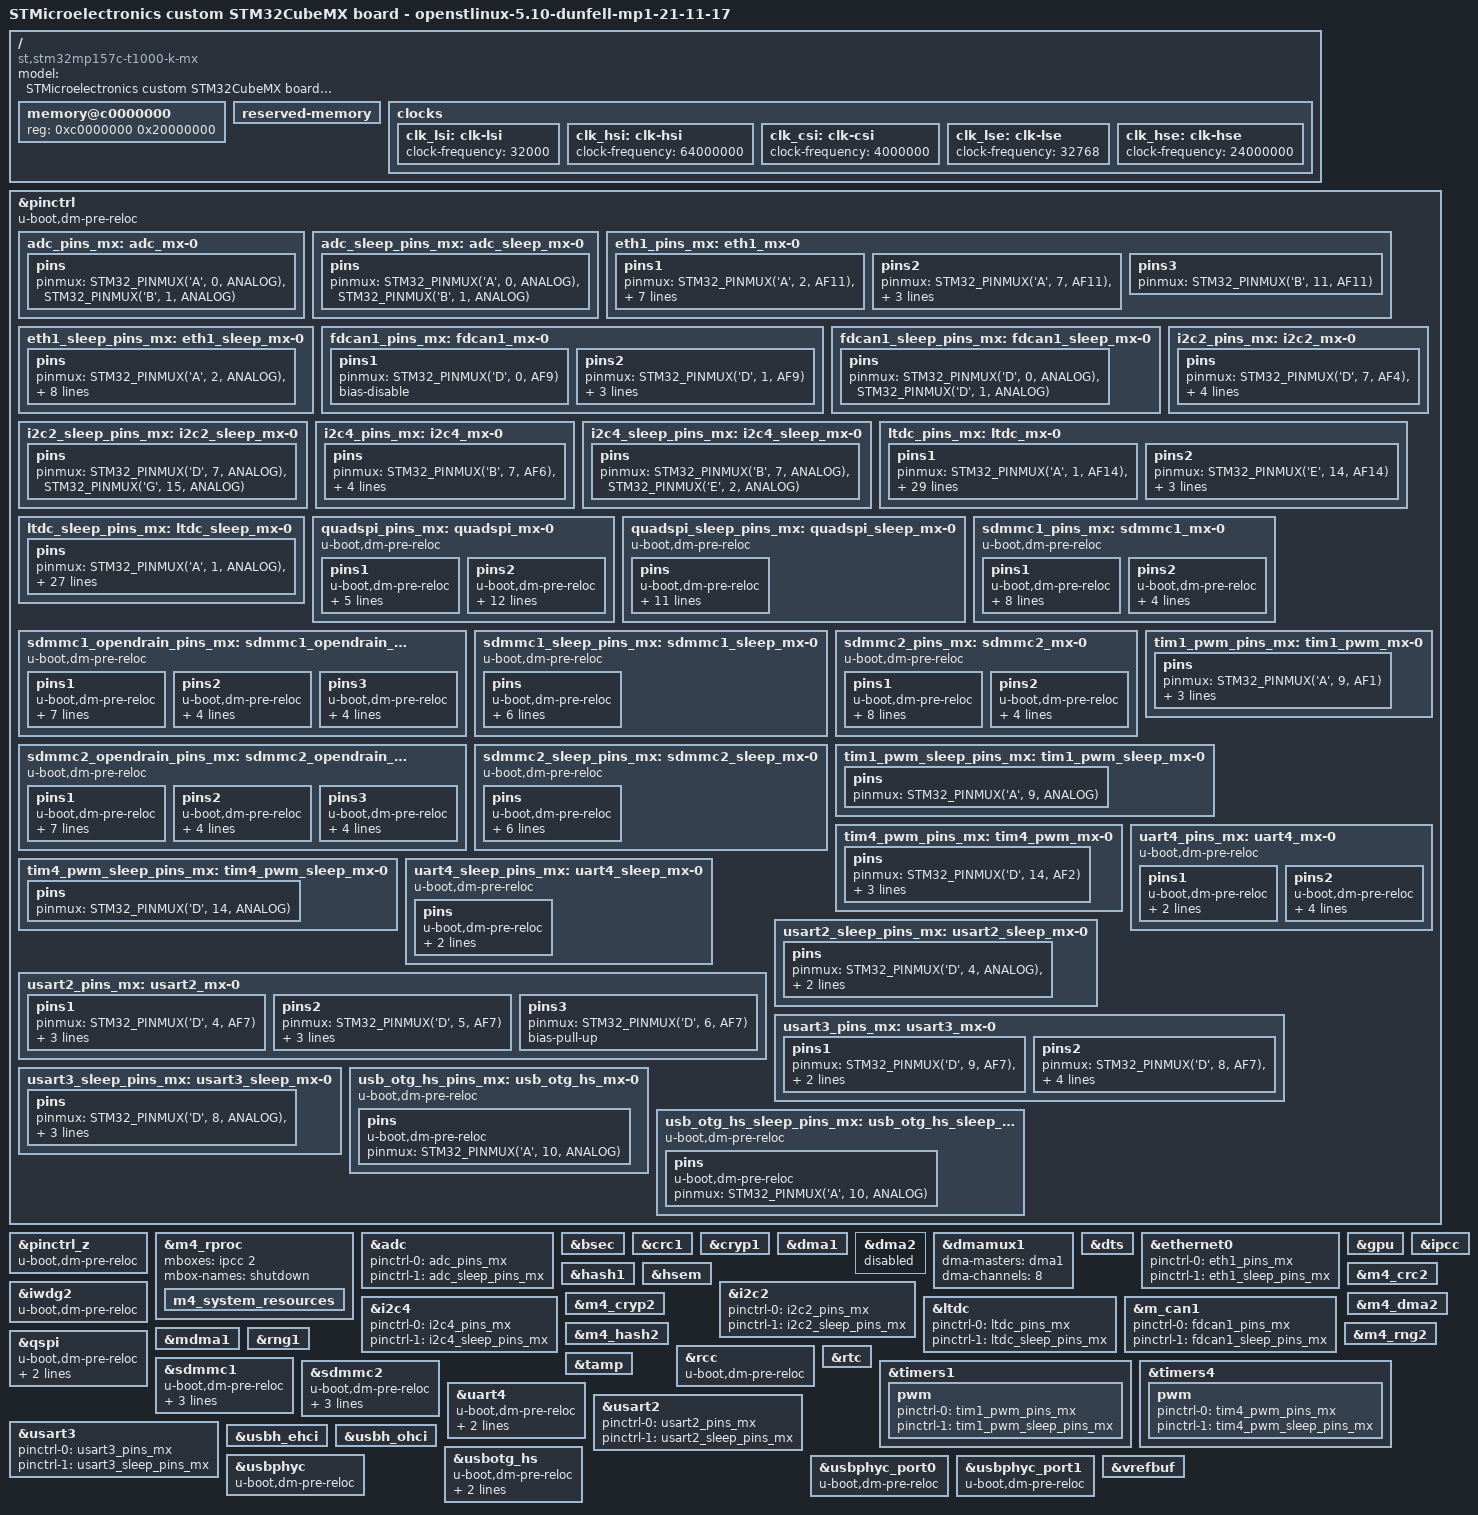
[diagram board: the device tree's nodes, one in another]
/* SPDX-License-Identifier: (GPL-2.0+ OR BSD-3-Clause) */
/*
 * Copyright (C) STMicroelectronics 2022 - All Rights Reserved
 * Author: STM32CubeMX code generation for STMicroelectronics.
 */

/* For more information on Device Tree configuration, please refer to
 * https://wiki.st.com/stm32mpu/wiki/Category:Device_tree_configuration
 */

/dts-v1/;
#include <dt-bindings/pinctrl/stm32-pinfunc.h>

#include "stm32mp157.dtsi"
#include "stm32mp15xc.dtsi"
#include "stm32mp15xxad-pinctrl.dtsi"
#include "stm32mp15-m4-srm.dtsi"

/* USER CODE BEGIN includes */
/* USER CODE END includes */

/ {
	model = "STMicroelectronics custom STM32CubeMX board - openstlinux-5.10-dunfell-mp1-21-11-17";
	compatible = "st,stm32mp157c-t1000-k-mx", "st,stm32mp157";

	memory@c0000000 {
		device_type = "memory";
		reg = <0xc0000000 0x20000000>;

		/* USER CODE BEGIN memory */
		/* USER CODE END memory */
	};

	reserved-memory {
		#address-cells = <1>;
		#size-cells = <1>;
		ranges;

		/* USER CODE BEGIN reserved-memory */
		/* USER CODE END reserved-memory */
	};

	/* USER CODE BEGIN root */
	/* USER CODE END root */

	clocks {
		/* USER CODE BEGIN clocks */
		/* USER CODE END clocks */

#ifndef CONFIG_TFABOOT
		clk_lsi: clk-lsi {
			clock-frequency = <32000>;
		};
		clk_hsi: clk-hsi {
			clock-frequency = <64000000>;
		};
		clk_csi: clk-csi {
			clock-frequency = <4000000>;
		};
		clk_lse: clk-lse {
			clock-frequency = <32768>;
		};
		clk_hse: clk-hse {
			clock-frequency = <24000000>;
		};
#endif	/*CONFIG_TFABOOT*/
	};

}; /*root*/

&pinctrl {
	u-boot,dm-pre-reloc;

	adc_pins_mx: adc_mx-0 {
		pins {
			pinmux = <STM32_PINMUX('A', 0, ANALOG)>, /* ADC1_INP16 */
					 <STM32_PINMUX('B', 1, ANALOG)>; /* ADC1_INP5 */
		};
	};

	adc_sleep_pins_mx: adc_sleep_mx-0 {
		pins {
			pinmux = <STM32_PINMUX('A', 0, ANALOG)>, /* ADC1_INP16 */
					 <STM32_PINMUX('B', 1, ANALOG)>; /* ADC1_INP5 */
		};
	};

	eth1_pins_mx: eth1_mx-0 {
		pins1 {
			pinmux = <STM32_PINMUX('A', 2, AF11)>, /* ETH1_MDIO */
					 <STM32_PINMUX('B', 12, AF11)>, /* ETH1_TXD0 */
					 <STM32_PINMUX('B', 13, AF11)>, /* ETH1_TXD1 */
					 <STM32_PINMUX('C', 1, AF11)>, /* ETH1_MDC */
					 <STM32_PINMUX('G', 8, AF2)>; /* ETH1_CLK */
			bias-disable;
			drive-push-pull;
			slew-rate = <1>;
		};
		pins2 {
			pinmux = <STM32_PINMUX('A', 7, AF11)>, /* ETH1_CRS_DV */
					 <STM32_PINMUX('C', 4, AF11)>, /* ETH1_RXD0 */
					 <STM32_PINMUX('C', 5, AF11)>; /* ETH1_RXD1 */
			bias-disable;
		};
		pins3 {
			pinmux = <STM32_PINMUX('B', 11, AF11)>; /* ETH1_TX_EN */
		};
	};

	eth1_sleep_pins_mx: eth1_sleep_mx-0 {
		pins {
			pinmux = <STM32_PINMUX('A', 2, ANALOG)>, /* ETH1_MDIO */
					 <STM32_PINMUX('A', 7, ANALOG)>, /* ETH1_CRS_DV */
					 <STM32_PINMUX('B', 11, ANALOG)>, /* ETH1_TX_EN */
					 <STM32_PINMUX('B', 12, ANALOG)>, /* ETH1_TXD0 */
					 <STM32_PINMUX('B', 13, ANALOG)>, /* ETH1_TXD1 */
					 <STM32_PINMUX('C', 1, ANALOG)>, /* ETH1_MDC */
					 <STM32_PINMUX('C', 4, ANALOG)>, /* ETH1_RXD0 */
					 <STM32_PINMUX('C', 5, ANALOG)>, /* ETH1_RXD1 */
					 <STM32_PINMUX('G', 8, ANALOG)>; /* ETH1_CLK */
		};
	};

	fdcan1_pins_mx: fdcan1_mx-0 {
		pins1 {
			pinmux = <STM32_PINMUX('D', 0, AF9)>; /* FDCAN1_RX */
			bias-disable;
		};
		pins2 {
			pinmux = <STM32_PINMUX('D', 1, AF9)>; /* FDCAN1_TX */
			bias-disable;
			drive-push-pull;
			slew-rate = <0>;
		};
	};

	fdcan1_sleep_pins_mx: fdcan1_sleep_mx-0 {
		pins {
			pinmux = <STM32_PINMUX('D', 0, ANALOG)>, /* FDCAN1_RX */
					 <STM32_PINMUX('D', 1, ANALOG)>; /* FDCAN1_TX */
		};
	};

	i2c2_pins_mx: i2c2_mx-0 {
		pins {
			pinmux = <STM32_PINMUX('D', 7, AF4)>, /* I2C2_SCL */
					 <STM32_PINMUX('G', 15, AF4)>; /* I2C2_SDA */
			bias-pull-up;
			drive-open-drain;
			slew-rate = <0>;
		};
	};

	i2c2_sleep_pins_mx: i2c2_sleep_mx-0 {
		pins {
			pinmux = <STM32_PINMUX('D', 7, ANALOG)>, /* I2C2_SCL */
					 <STM32_PINMUX('G', 15, ANALOG)>; /* I2C2_SDA */
		};
	};

	i2c4_pins_mx: i2c4_mx-0 {
		pins {
			pinmux = <STM32_PINMUX('B', 7, AF6)>, /* I2C4_SDA */
					 <STM32_PINMUX('E', 2, AF4)>; /* I2C4_SCL */
			bias-pull-up;
			drive-open-drain;
			slew-rate = <0>;
		};
	};

	i2c4_sleep_pins_mx: i2c4_sleep_mx-0 {
		pins {
			pinmux = <STM32_PINMUX('B', 7, ANALOG)>, /* I2C4_SDA */
					 <STM32_PINMUX('E', 2, ANALOG)>; /* I2C4_SCL */
		};
	};

	ltdc_pins_mx: ltdc_mx-0 {
		pins1 {
			pinmux = <STM32_PINMUX('A', 1, AF14)>, /* LTDC_R2 */
					 <STM32_PINMUX('A', 3, AF14)>, /* LTDC_B5 */
					 <STM32_PINMUX('A', 4, AF14)>, /* LTDC_VSYNC */
					 <STM32_PINMUX('A', 5, AF14)>, /* LTDC_R4 */
					 <STM32_PINMUX('A', 6, AF14)>, /* LTDC_G2 */
					 <STM32_PINMUX('A', 8, AF14)>, /* LTDC_R6 */
					 <STM32_PINMUX('A', 12, AF14)>, /* LTDC_R5 */
					 <STM32_PINMUX('A', 15, AF14)>, /* LTDC_R1 */
					 <STM32_PINMUX('B', 0, AF9)>, /* LTDC_R3 */
					 <STM32_PINMUX('B', 5, AF14)>, /* LTDC_G7 */
					 <STM32_PINMUX('B', 8, AF14)>, /* LTDC_B6 */
					 <STM32_PINMUX('B', 9, AF14)>, /* LTDC_B7 */
					 <STM32_PINMUX('B', 10, AF14)>, /* LTDC_G4 */
					 <STM32_PINMUX('C', 6, AF14)>, /* LTDC_HSYNC */
					 <STM32_PINMUX('C', 7, AF14)>, /* LTDC_G6 */
					 <STM32_PINMUX('D', 10, AF14)>, /* LTDC_B3 */
					 <STM32_PINMUX('E', 4, AF14)>, /* LTDC_B0 */
					 <STM32_PINMUX('E', 5, AF14)>, /* LTDC_G0 */
					 <STM32_PINMUX('E', 6, AF14)>, /* LTDC_G1 */
					 <STM32_PINMUX('E', 11, AF14)>, /* LTDC_G3 */
					 <STM32_PINMUX('E', 12, AF14)>, /* LTDC_B4 */
					 <STM32_PINMUX('E', 13, AF14)>, /* LTDC_DE */
					 <STM32_PINMUX('E', 15, AF14)>, /* LTDC_R7 */
					 <STM32_PINMUX('F', 11, AF14)>, /* LTDC_G5 */
					 <STM32_PINMUX('G', 10, AF14)>, /* LTDC_B2 */
					 <STM32_PINMUX('G', 12, AF14)>, /* LTDC_B1 */
					 <STM32_PINMUX('G', 13, AF14)>; /* LTDC_R0 */
			bias-disable;
			drive-push-pull;
			slew-rate = <0>;
		};
		pins2 {
			pinmux = <STM32_PINMUX('E', 14, AF14)>; /* LTDC_CLK */
			bias-disable;
			drive-push-pull;
			slew-rate = <1>;
		};
	};

	ltdc_sleep_pins_mx: ltdc_sleep_mx-0 {
		pins {
			pinmux = <STM32_PINMUX('A', 1, ANALOG)>, /* LTDC_R2 */
					 <STM32_PINMUX('A', 3, ANALOG)>, /* LTDC_B5 */
					 <STM32_PINMUX('A', 4, ANALOG)>, /* LTDC_VSYNC */
					 <STM32_PINMUX('A', 5, ANALOG)>, /* LTDC_R4 */
					 <STM32_PINMUX('A', 6, ANALOG)>, /* LTDC_G2 */
					 <STM32_PINMUX('A', 8, ANALOG)>, /* LTDC_R6 */
					 <STM32_PINMUX('A', 12, ANALOG)>, /* LTDC_R5 */
					 <STM32_PINMUX('A', 15, ANALOG)>, /* LTDC_R1 */
					 <STM32_PINMUX('B', 0, ANALOG)>, /* LTDC_R3 */
					 <STM32_PINMUX('B', 5, ANALOG)>, /* LTDC_G7 */
					 <STM32_PINMUX('B', 8, ANALOG)>, /* LTDC_B6 */
					 <STM32_PINMUX('B', 9, ANALOG)>, /* LTDC_B7 */
					 <STM32_PINMUX('B', 10, ANALOG)>, /* LTDC_G4 */
					 <STM32_PINMUX('C', 6, ANALOG)>, /* LTDC_HSYNC */
					 <STM32_PINMUX('C', 7, ANALOG)>, /* LTDC_G6 */
					 <STM32_PINMUX('D', 10, ANALOG)>, /* LTDC_B3 */
					 <STM32_PINMUX('E', 4, ANALOG)>, /* LTDC_B0 */
					 <STM32_PINMUX('E', 5, ANALOG)>, /* LTDC_G0 */
					 <STM32_PINMUX('E', 6, ANALOG)>, /* LTDC_G1 */
					 <STM32_PINMUX('E', 11, ANALOG)>, /* LTDC_G3 */
					 <STM32_PINMUX('E', 12, ANALOG)>, /* LTDC_B4 */
					 <STM32_PINMUX('E', 13, ANALOG)>, /* LTDC_DE */
					 <STM32_PINMUX('E', 14, ANALOG)>, /* LTDC_CLK */
					 <STM32_PINMUX('E', 15, ANALOG)>, /* LTDC_R7 */
					 <STM32_PINMUX('F', 11, ANALOG)>, /* LTDC_G5 */
					 <STM32_PINMUX('G', 10, ANALOG)>, /* LTDC_B2 */
					 <STM32_PINMUX('G', 12, ANALOG)>, /* LTDC_B1 */
					 <STM32_PINMUX('G', 13, ANALOG)>; /* LTDC_R0 */
		};
	};

	quadspi_pins_mx: quadspi_mx-0 {
		u-boot,dm-pre-reloc;
		pins1 {
			u-boot,dm-pre-reloc;
			pinmux = <STM32_PINMUX('B', 6, AF10)>, /* QUADSPI_BK1_NCS */
					 <STM32_PINMUX('C', 0, AF10)>; /* QUADSPI_BK2_NCS */
			bias-pull-up;
			drive-push-pull;
			slew-rate = <3>;
		};
		pins2 {
			u-boot,dm-pre-reloc;
			pinmux = <STM32_PINMUX('E', 7, AF10)>, /* QUADSPI_BK2_IO0 */
					 <STM32_PINMUX('E', 8, AF10)>, /* QUADSPI_BK2_IO1 */
					 <STM32_PINMUX('E', 9, AF10)>, /* QUADSPI_BK2_IO2 */
					 <STM32_PINMUX('E', 10, AF10)>, /* QUADSPI_BK2_IO3 */
					 <STM32_PINMUX('F', 6, AF9)>, /* QUADSPI_BK1_IO3 */
					 <STM32_PINMUX('F', 7, AF9)>, /* QUADSPI_BK1_IO2 */
					 <STM32_PINMUX('F', 8, AF10)>, /* QUADSPI_BK1_IO0 */
					 <STM32_PINMUX('F', 9, AF10)>, /* QUADSPI_BK1_IO1 */
					 <STM32_PINMUX('F', 10, AF9)>; /* QUADSPI_CLK */
			bias-disable;
			drive-push-pull;
			slew-rate = <3>;
		};
	};

	quadspi_sleep_pins_mx: quadspi_sleep_mx-0 {
		u-boot,dm-pre-reloc;
		pins {
			u-boot,dm-pre-reloc;
			pinmux = <STM32_PINMUX('B', 6, ANALOG)>, /* QUADSPI_BK1_NCS */
					 <STM32_PINMUX('C', 0, ANALOG)>, /* QUADSPI_BK2_NCS */
					 <STM32_PINMUX('E', 7, ANALOG)>, /* QUADSPI_BK2_IO0 */
					 <STM32_PINMUX('E', 8, ANALOG)>, /* QUADSPI_BK2_IO1 */
					 <STM32_PINMUX('E', 9, ANALOG)>, /* QUADSPI_BK2_IO2 */
					 <STM32_PINMUX('E', 10, ANALOG)>, /* QUADSPI_BK2_IO3 */
					 <STM32_PINMUX('F', 6, ANALOG)>, /* QUADSPI_BK1_IO3 */
					 <STM32_PINMUX('F', 7, ANALOG)>, /* QUADSPI_BK1_IO2 */
					 <STM32_PINMUX('F', 8, ANALOG)>, /* QUADSPI_BK1_IO0 */
					 <STM32_PINMUX('F', 9, ANALOG)>, /* QUADSPI_BK1_IO1 */
					 <STM32_PINMUX('F', 10, ANALOG)>; /* QUADSPI_CLK */
		};
	};

	sdmmc1_pins_mx: sdmmc1_mx-0 {
		u-boot,dm-pre-reloc;
		pins1 {
			u-boot,dm-pre-reloc;
			pinmux = <STM32_PINMUX('C', 8, AF12)>, /* SDMMC1_D0 */
					 <STM32_PINMUX('C', 9, AF12)>, /* SDMMC1_D1 */
					 <STM32_PINMUX('C', 10, AF12)>, /* SDMMC1_D2 */
					 <STM32_PINMUX('C', 11, AF12)>, /* SDMMC1_D3 */
					 <STM32_PINMUX('D', 2, AF12)>; /* SDMMC1_CMD */
			bias-pull-up;
			drive-push-pull;
			slew-rate = <1>;
		};
		pins2 {
			u-boot,dm-pre-reloc;
			pinmux = <STM32_PINMUX('C', 12, AF12)>; /* SDMMC1_CK */
			bias-pull-up;
			drive-push-pull;
			slew-rate = <3>;
		};
	};

	sdmmc1_opendrain_pins_mx: sdmmc1_opendrain_mx-0 {
		u-boot,dm-pre-reloc;
		pins1 {
			u-boot,dm-pre-reloc;
			pinmux = <STM32_PINMUX('C', 8, AF12)>, /* SDMMC1_D0 */
					 <STM32_PINMUX('C', 9, AF12)>, /* SDMMC1_D1 */
					 <STM32_PINMUX('C', 10, AF12)>, /* SDMMC1_D2 */
					 <STM32_PINMUX('C', 11, AF12)>; /* SDMMC1_D3 */
			bias-pull-up;
			drive-push-pull;
			slew-rate = <1>;
		};
		pins2 {
			u-boot,dm-pre-reloc;
			pinmux = <STM32_PINMUX('C', 12, AF12)>; /* SDMMC1_CK */
			bias-pull-up;
			drive-push-pull;
			slew-rate = <3>;
		};
		pins3 {
			u-boot,dm-pre-reloc;
			pinmux = <STM32_PINMUX('D', 2, AF12)>; /* SDMMC1_CMD */
			bias-pull-up;
			drive-open-drain;
			slew-rate = <1>;
		};
	};

	sdmmc1_sleep_pins_mx: sdmmc1_sleep_mx-0 {
		u-boot,dm-pre-reloc;
		pins {
			u-boot,dm-pre-reloc;
			pinmux = <STM32_PINMUX('C', 8, ANALOG)>, /* SDMMC1_D0 */
					 <STM32_PINMUX('C', 9, ANALOG)>, /* SDMMC1_D1 */
					 <STM32_PINMUX('C', 10, ANALOG)>, /* SDMMC1_D2 */
					 <STM32_PINMUX('C', 11, ANALOG)>, /* SDMMC1_D3 */
					 <STM32_PINMUX('C', 12, ANALOG)>, /* SDMMC1_CK */
					 <STM32_PINMUX('D', 2, ANALOG)>; /* SDMMC1_CMD */
		};
	};

	sdmmc2_pins_mx: sdmmc2_mx-0 {
		u-boot,dm-pre-reloc;
		pins1 {
			u-boot,dm-pre-reloc;
			pinmux = <STM32_PINMUX('B', 3, AF9)>, /* SDMMC2_D2 */
					 <STM32_PINMUX('B', 4, AF9)>, /* SDMMC2_D3 */
					 <STM32_PINMUX('B', 14, AF9)>, /* SDMMC2_D0 */
					 <STM32_PINMUX('B', 15, AF9)>, /* SDMMC2_D1 */
					 <STM32_PINMUX('G', 6, AF10)>; /* SDMMC2_CMD */
			bias-pull-up;
			drive-push-pull;
			slew-rate = <1>;
		};
		pins2 {
			u-boot,dm-pre-reloc;
			pinmux = <STM32_PINMUX('E', 3, AF9)>; /* SDMMC2_CK */
			bias-pull-up;
			drive-push-pull;
			slew-rate = <3>;
		};
	};

	sdmmc2_opendrain_pins_mx: sdmmc2_opendrain_mx-0 {
		u-boot,dm-pre-reloc;
		pins1 {
			u-boot,dm-pre-reloc;
			pinmux = <STM32_PINMUX('B', 3, AF9)>, /* SDMMC2_D2 */
					 <STM32_PINMUX('B', 4, AF9)>, /* SDMMC2_D3 */
					 <STM32_PINMUX('B', 14, AF9)>, /* SDMMC2_D0 */
					 <STM32_PINMUX('B', 15, AF9)>; /* SDMMC2_D1 */
			bias-pull-up;
			drive-push-pull;
			slew-rate = <1>;
		};
		pins2 {
			u-boot,dm-pre-reloc;
			pinmux = <STM32_PINMUX('E', 3, AF9)>; /* SDMMC2_CK */
			bias-pull-up;
			drive-push-pull;
			slew-rate = <3>;
		};
		pins3 {
			u-boot,dm-pre-reloc;
			pinmux = <STM32_PINMUX('G', 6, AF10)>; /* SDMMC2_CMD */
			bias-pull-up;
			drive-open-drain;
			slew-rate = <1>;
		};
	};

	sdmmc2_sleep_pins_mx: sdmmc2_sleep_mx-0 {
		u-boot,dm-pre-reloc;
		pins {
			u-boot,dm-pre-reloc;
			pinmux = <STM32_PINMUX('B', 3, ANALOG)>, /* SDMMC2_D2 */
					 <STM32_PINMUX('B', 4, ANALOG)>, /* SDMMC2_D3 */
					 <STM32_PINMUX('B', 14, ANALOG)>, /* SDMMC2_D0 */
					 <STM32_PINMUX('B', 15, ANALOG)>, /* SDMMC2_D1 */
					 <STM32_PINMUX('E', 3, ANALOG)>, /* SDMMC2_CK */
					 <STM32_PINMUX('G', 6, ANALOG)>; /* SDMMC2_CMD */
		};
	};

	tim1_pwm_pins_mx: tim1_pwm_mx-0 {
		pins {
			pinmux = <STM32_PINMUX('A', 9, AF1)>; /* TIM1_CH2 */
			bias-disable;
			drive-push-pull;
			slew-rate = <0>;
		};
	};

	tim1_pwm_sleep_pins_mx: tim1_pwm_sleep_mx-0 {
		pins {
			pinmux = <STM32_PINMUX('A', 9, ANALOG)>; /* TIM1_CH2 */
		};
	};

	tim4_pwm_pins_mx: tim4_pwm_mx-0 {
		pins {
			pinmux = <STM32_PINMUX('D', 14, AF2)>; /* TIM4_CH3 */
			bias-disable;
			drive-push-pull;
			slew-rate = <0>;
		};
	};

	tim4_pwm_sleep_pins_mx: tim4_pwm_sleep_mx-0 {
		pins {
			pinmux = <STM32_PINMUX('D', 14, ANALOG)>; /* TIM4_CH3 */
		};
	};

	uart4_pins_mx: uart4_mx-0 {
		u-boot,dm-pre-reloc;
		pins1 {
			u-boot,dm-pre-reloc;
			pinmux = <STM32_PINMUX('B', 2, AF8)>; /* UART4_RX */
			bias-pull-up;
		};
		pins2 {
			u-boot,dm-pre-reloc;
			pinmux = <STM32_PINMUX('G', 11, AF6)>; /* UART4_TX */
			bias-pull-up;
			drive-push-pull;
			slew-rate = <0>;
		};
	};

	uart4_sleep_pins_mx: uart4_sleep_mx-0 {
		u-boot,dm-pre-reloc;
		pins {
			u-boot,dm-pre-reloc;
			pinmux = <STM32_PINMUX('B', 2, ANALOG)>, /* UART4_RX */
					 <STM32_PINMUX('G', 11, ANALOG)>; /* UART4_TX */
		};
	};

	usart2_pins_mx: usart2_mx-0 {
		pins1 {
			pinmux = <STM32_PINMUX('D', 4, AF7)>; /* USART2_RTS */
			bias-pull-down;
			drive-push-pull;
			slew-rate = <0>;
		};
		pins2 {
			pinmux = <STM32_PINMUX('D', 5, AF7)>; /* USART2_TX */
			bias-pull-up;
			drive-push-pull;
			slew-rate = <0>;
		};
		pins3 {
			pinmux = <STM32_PINMUX('D', 6, AF7)>; /* USART2_RX */
			bias-pull-up;
		};
	};

	usart2_sleep_pins_mx: usart2_sleep_mx-0 {
		pins {
			pinmux = <STM32_PINMUX('D', 4, ANALOG)>, /* USART2_RTS */
					 <STM32_PINMUX('D', 5, ANALOG)>, /* USART2_TX */
					 <STM32_PINMUX('D', 6, ANALOG)>; /* USART2_RX */
		};
	};

	usart3_pins_mx: usart3_mx-0 {
		pins1 {
			pinmux = <STM32_PINMUX('D', 9, AF7)>, /* USART3_RX */
					 <STM32_PINMUX('D', 11, AF7)>; /* USART3_CTS */
			bias-disable;
		};
		pins2 {
			pinmux = <STM32_PINMUX('D', 8, AF7)>, /* USART3_TX */
					 <STM32_PINMUX('D', 12, AF7)>; /* USART3_RTS */
			bias-disable;
			drive-push-pull;
			slew-rate = <0>;
		};
	};

	usart3_sleep_pins_mx: usart3_sleep_mx-0 {
		pins {
			pinmux = <STM32_PINMUX('D', 8, ANALOG)>, /* USART3_TX */
					 <STM32_PINMUX('D', 9, ANALOG)>, /* USART3_RX */
					 <STM32_PINMUX('D', 11, ANALOG)>, /* USART3_CTS */
					 <STM32_PINMUX('D', 12, ANALOG)>; /* USART3_RTS */
		};
	};

	usb_otg_hs_pins_mx: usb_otg_hs_mx-0 {
		u-boot,dm-pre-reloc;
		pins {
			u-boot,dm-pre-reloc;
			pinmux = <STM32_PINMUX('A', 10, ANALOG)>; /* USB_OTG_HS_ID */
		};
	};

	usb_otg_hs_sleep_pins_mx: usb_otg_hs_sleep_mx-0 {
		u-boot,dm-pre-reloc;
		pins {
			u-boot,dm-pre-reloc;
			pinmux = <STM32_PINMUX('A', 10, ANALOG)>; /* USB_OTG_HS_ID */
		};
	};

	/* USER CODE BEGIN pinctrl */
	/* USER CODE END pinctrl */
};

&pinctrl_z {
	u-boot,dm-pre-reloc;

	/* USER CODE BEGIN pinctrl_z */
	/* USER CODE END pinctrl_z */
};

&m4_rproc{
	/*Restriction: "memory-region" property is not managed - please to use User-Section if needed*/
	mboxes = <&ipcc 2>;
	mbox-names = "shutdown";
	status = "okay";

	/* USER CODE BEGIN m4_rproc */
	/* USER CODE END m4_rproc */

	m4_system_resources{
		status = "okay";

		/* USER CODE BEGIN m4_system_resources */
		/* USER CODE END m4_system_resources */
	};
};

&adc{
	pinctrl-names = "default", "sleep";
	pinctrl-0 = <&adc_pins_mx>;
	pinctrl-1 = <&adc_sleep_pins_mx>;
	status = "okay";

	/* USER CODE BEGIN adc */
	/* USER CODE END adc */
};

&bsec{
	status = "okay";

	/* USER CODE BEGIN bsec */
	/* USER CODE END bsec */
};

&crc1{
	status = "okay";

	/* USER CODE BEGIN crc1 */
	/* USER CODE END crc1 */
};

&cryp1{
	status = "okay";

	/* USER CODE BEGIN cryp1 */
	/* USER CODE END cryp1 */
};

&dma1{
	status = "okay";

	/* USER CODE BEGIN dma1 */
	/* USER CODE END dma1 */
};

&dma2{
	status = "disabled";

	/* USER CODE BEGIN dma2 */
	/* USER CODE END dma2 */
};

&dmamux1{
	status = "okay";

	dma-masters = <&dma1>;
	dma-channels = <8>;

	/* USER CODE BEGIN dmamux1 */
	/* USER CODE END dmamux1 */
};

&dts{
	status = "okay";

	/* USER CODE BEGIN dts */
	/* USER CODE END dts */
};

&ethernet0{
	pinctrl-names = "default", "sleep";
	pinctrl-0 = <&eth1_pins_mx>;
	pinctrl-1 = <&eth1_sleep_pins_mx>;
	status = "okay";

	/* USER CODE BEGIN ethernet0 */
	/* USER CODE END ethernet0 */
};

&gpu{
	status = "okay";

	/* USER CODE BEGIN gpu */
	/* USER CODE END gpu */
};

&hash1{
	status = "okay";

	/* USER CODE BEGIN hash1 */
	/* USER CODE END hash1 */
};

&hsem{
	status = "okay";

	/* USER CODE BEGIN hsem */
	/* USER CODE END hsem */
};

&i2c2{
	pinctrl-names = "default", "sleep";
	pinctrl-0 = <&i2c2_pins_mx>;
	pinctrl-1 = <&i2c2_sleep_pins_mx>;
	status = "okay";

	/* USER CODE BEGIN i2c2 */
	/* USER CODE END i2c2 */
};

&i2c4{
	pinctrl-names = "default", "sleep";
	pinctrl-0 = <&i2c4_pins_mx>;
	pinctrl-1 = <&i2c4_sleep_pins_mx>;
	status = "okay";

	/* USER CODE BEGIN i2c4 */
	/* USER CODE END i2c4 */
};

&ipcc{
	status = "okay";

	/* USER CODE BEGIN ipcc */
	/* USER CODE END ipcc */
};

&iwdg2{
	u-boot,dm-pre-reloc;
	status = "okay";

	/* USER CODE BEGIN iwdg2 */
	/* USER CODE END iwdg2 */
};

&ltdc{
	pinctrl-names = "default", "sleep";
	pinctrl-0 = <&ltdc_pins_mx>;
	pinctrl-1 = <&ltdc_sleep_pins_mx>;
	status = "okay";

	/* USER CODE BEGIN ltdc */
	/* USER CODE END ltdc */
};

&m_can1{
	pinctrl-names = "default", "sleep";
	pinctrl-0 = <&fdcan1_pins_mx>;
	pinctrl-1 = <&fdcan1_sleep_pins_mx>;
	status = "okay";

	/* USER CODE BEGIN m_can1 */
	/* USER CODE END m_can1 */
};

&m4_crc2{
	status = "okay";

	/* USER CODE BEGIN m4_crc2 */
	/* USER CODE END m4_crc2 */
};

&m4_cryp2{
	status = "okay";

	/* USER CODE BEGIN m4_cryp2 */
	/* USER CODE END m4_cryp2 */
};

&m4_dma2{
	status = "okay";

	/* USER CODE BEGIN m4_dma2 */
	/* USER CODE END m4_dma2 */
};

&m4_hash2{
	status = "okay";

	/* USER CODE BEGIN m4_hash2 */
	/* USER CODE END m4_hash2 */
};

&m4_rng2{
	status = "okay";

	/* USER CODE BEGIN m4_rng2 */
	/* USER CODE END m4_rng2 */
};

&mdma1{
	status = "okay";

	/* USER CODE BEGIN mdma1 */
	/* USER CODE END mdma1 */
};

&qspi{
	u-boot,dm-pre-reloc;
	pinctrl-names = "default", "sleep";
	pinctrl-0 = <&quadspi_pins_mx>;
	pinctrl-1 = <&quadspi_sleep_pins_mx>;
	status = "okay";

	/* USER CODE BEGIN qspi */
	/* USER CODE END qspi */
};

&rcc{
	u-boot,dm-pre-reloc;
	status = "okay";

	/* USER CODE BEGIN rcc */
	/* USER CODE END rcc */
};

&rng1{
	status = "okay";

	/* USER CODE BEGIN rng1 */
	/* USER CODE END rng1 */
};

&rtc{
	status = "okay";

	/* USER CODE BEGIN rtc */
	/* USER CODE END rtc */
};

&sdmmc1{
	u-boot,dm-pre-reloc;
	pinctrl-names = "default", "opendrain", "sleep";
	pinctrl-0 = <&sdmmc1_pins_mx>;
	pinctrl-1 = <&sdmmc1_opendrain_pins_mx>;
	pinctrl-2 = <&sdmmc1_sleep_pins_mx>;
	status = "okay";

	/* USER CODE BEGIN sdmmc1 */
	/* USER CODE END sdmmc1 */
};

&sdmmc2{
	u-boot,dm-pre-reloc;
	pinctrl-names = "default", "opendrain", "sleep";
	pinctrl-0 = <&sdmmc2_pins_mx>;
	pinctrl-1 = <&sdmmc2_opendrain_pins_mx>;
	pinctrl-2 = <&sdmmc2_sleep_pins_mx>;
	status = "okay";

	/* USER CODE BEGIN sdmmc2 */
	/* USER CODE END sdmmc2 */
};

&tamp{
	status = "okay";

	/* USER CODE BEGIN tamp */
	/* USER CODE END tamp */
};

&timers1{
	status = "okay";

	/* USER CODE BEGIN timers1 */
	/* USER CODE END timers1 */

	pwm{
		pinctrl-names = "default", "sleep";
		pinctrl-0 = <&tim1_pwm_pins_mx>;
		pinctrl-1 = <&tim1_pwm_sleep_pins_mx>;
		status = "okay";

		/* USER CODE BEGIN timers1_pwm */
		/* USER CODE END timers1_pwm */
	};
};

&timers4{
	status = "okay";

	/* USER CODE BEGIN timers4 */
	/* USER CODE END timers4 */

	pwm{
		pinctrl-names = "default", "sleep";
		pinctrl-0 = <&tim4_pwm_pins_mx>;
		pinctrl-1 = <&tim4_pwm_sleep_pins_mx>;
		status = "okay";

		/* USER CODE BEGIN timers4_pwm */
		/* USER CODE END timers4_pwm */
	};
};

&uart4{
	u-boot,dm-pre-reloc;
	pinctrl-names = "default", "sleep";
	pinctrl-0 = <&uart4_pins_mx>;
	pinctrl-1 = <&uart4_sleep_pins_mx>;
	status = "okay";

	/* USER CODE BEGIN uart4 */
	/* USER CODE END uart4 */
};

&usart2{
	pinctrl-names = "default", "sleep";
	pinctrl-0 = <&usart2_pins_mx>;
	pinctrl-1 = <&usart2_sleep_pins_mx>;
	status = "okay";

	/* USER CODE BEGIN usart2 */
	/* USER CODE END usart2 */
};

&usart3{
	pinctrl-names = "default", "sleep";
	pinctrl-0 = <&usart3_pins_mx>;
	pinctrl-1 = <&usart3_sleep_pins_mx>;
	status = "okay";

	/* USER CODE BEGIN usart3 */
	/* USER CODE END usart3 */
};

&usbh_ehci{
	status = "okay";

	/* USER CODE BEGIN usbh_ehci */
	/* USER CODE END usbh_ehci */
};

&usbh_ohci{
	status = "okay";

	/* USER CODE BEGIN usbh_ohci */
	/* USER CODE END usbh_ohci */
};

&usbotg_hs{
	u-boot,dm-pre-reloc;
	pinctrl-names = "default", "sleep";
	pinctrl-0 = <&usb_otg_hs_pins_mx>;
	pinctrl-1 = <&usb_otg_hs_sleep_pins_mx>;
	status = "okay";

	/* USER CODE BEGIN usbotg_hs */
	/* USER CODE END usbotg_hs */
};

&usbphyc{
	u-boot,dm-pre-reloc;
	status = "okay";

	/* USER CODE BEGIN usbphyc */
	/* USER CODE END usbphyc */
};

&usbphyc_port0{
	u-boot,dm-pre-reloc;
	status = "okay";

	/* USER CODE BEGIN usbphyc_port0 */
	/* USER CODE END usbphyc_port0 */
};

&usbphyc_port1{
	u-boot,dm-pre-reloc;
	status = "okay";

	/* USER CODE BEGIN usbphyc_port1 */
	/* USER CODE END usbphyc_port1 */
};

&vrefbuf{
	status = "okay";

	/* USER CODE BEGIN vrefbuf */
	/* USER CODE END vrefbuf */
};

/* USER CODE BEGIN addons */
/* USER CODE END addons */

